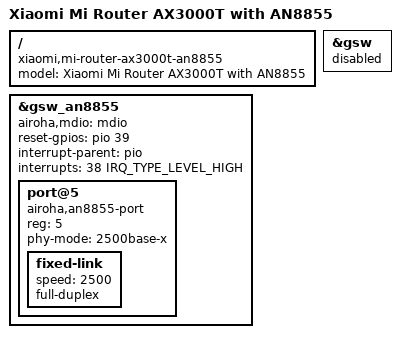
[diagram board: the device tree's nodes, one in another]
// SPDX-License-Identifier: GPL-2.0-or-later OR MIT

/dts-v1/;
#include "mt7981-xiaomi-mi-router-ax3000t.dts"

/ { 
	model = "Xiaomi Mi Router AX3000T with AN8855";
	compatible = "xiaomi,mi-router-ax3000t-an8855", "mediatek,mt7981";
};

&gsw {
	status = "disabled";
};

&gsw_an8855 {
	airoha,mdio = <&mdio>;
	reset-gpios = <&pio 39 0>;
	interrupt-parent = <&pio>;
	interrupts = <38 IRQ_TYPE_LEVEL_HIGH>;
	status = "okay";

	port@5 {
		compatible = "airoha,an8855-port";
		reg = <5>;
		phy-mode = "2500base-x";

		fixed-link {
			speed = <2500>;
			full-duplex;
		};
	};
};
